# M0 register map
Registers are 32-bit, read-write, reset 0x0 unless marked. A register's access mark holds for its fields unless they carry their own. Offsets are from the block's base; lines under a group give offsets from that group; [hi:lo] are bit positions; {n}, {i} and the like mark numbered series; 'fields as' and 'values as' point back to an identical list; <NAME> marks a mode.

## Memory map
0xE000E010 STK size 0x11 — SysTick timer
0xE000E100 NVIC size 0x33D — Nested Vectored Interrupt Controller
0xE000ED00 SCB size 0x41 — System control block

## NVIC — Nested Vectored Interrupt Controller
Base 0xE000E100
0x00 ISER — Interrupt Set Enable Register
  [31:0] SETENA
0x80 ICER — Interrupt Clear Enable Register
  [31:0] CLRENA
0x100 ISPR — Interrupt Set-Pending Register
  [31:0] SETPEND
0x180 ICPR — Interrupt Clear-Pending Register
  [31:0] CLRPEND
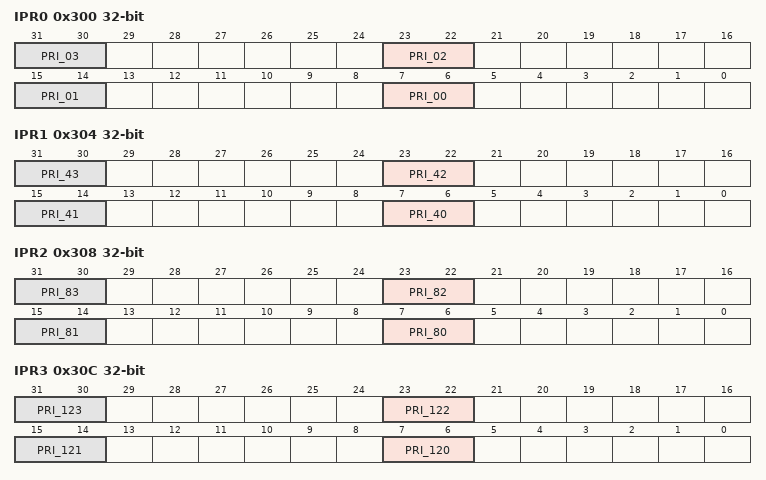
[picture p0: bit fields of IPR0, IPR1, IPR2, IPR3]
0x300 IPR0 — Interrupt Priority Register 0
  [8n+7:8n+6] PRI_{n:02} (n=0..3)
0x304 IPR1 — Interrupt Priority Register 1
  [8n-313:8n-314] PRI_{n} (n=40..43)
0x308 IPR2 — Interrupt Priority Register 2
  [8n-633:8n-634] PRI_{n} (n=80..83)
0x30C IPR3 — Interrupt Priority Register 3
  [8n-953:8n-954] PRI_{n} (n=120..123)
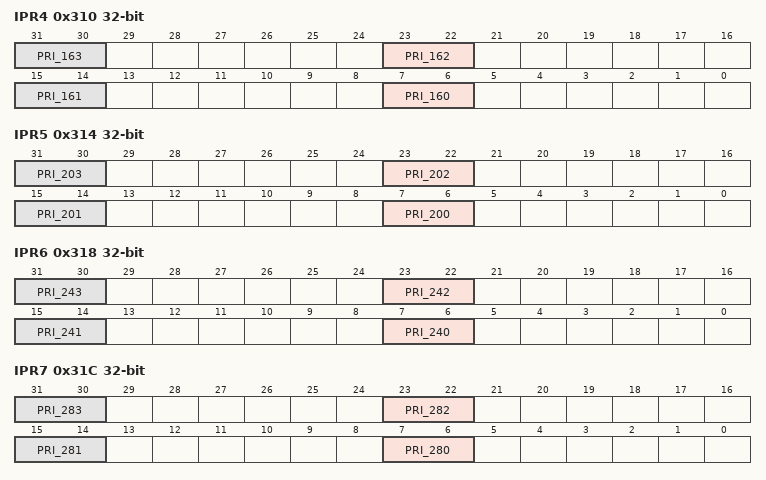
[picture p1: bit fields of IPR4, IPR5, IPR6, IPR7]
0x310 IPR4 — Interrupt Priority Register 4
  [8n-1273:8n-1274] PRI_{n} (n=160..163)
0x314 IPR5 — Interrupt Priority Register 5
  [8n-1593:8n-1594] PRI_{n} (n=200..203)
0x318 IPR6 — Interrupt Priority Register 6
  [8n-1913:8n-1914] PRI_{n} (n=240..243)
0x31C IPR7 — Interrupt Priority Register 7
  [8n-2233:8n-2234] PRI_{n} (n=280..283)

## SCB — System control block
Base 0xE000ED00
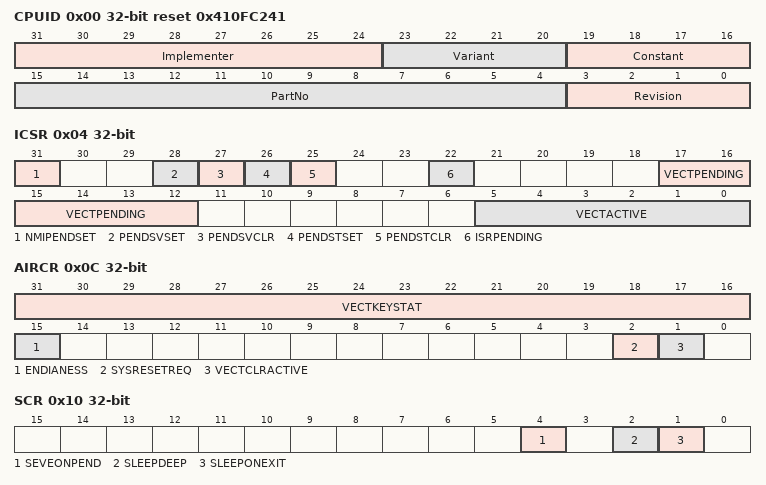
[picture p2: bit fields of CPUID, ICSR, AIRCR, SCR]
0x00 CPUID ro reset 0x410FC241 — CPUID base register
  [31:24] Implementer — Implementer code
  [23:20] Variant — Variant number
  [19:16] Constant — Reads as 0xF
  [15:4] PartNo — Part number of the processor
  [3:0] Revision — Revision number
0x04 ICSR — Interrupt control and state register
  [31] NMIPENDSET — NMI set-pending bit.
  [28] PENDSVSET — PendSV set-pending bit
  [27] PENDSVCLR — PendSV clear-pending bit
  [26] PENDSTSET — SysTick exception set-pending bit
  [25] PENDSTCLR — SysTick exception clear-pending bit
  [22] ISRPENDING — Interrupt pending flag
  [17:12] VECTPENDING — Pending vector
  [5:0] VECTACTIVE — Active vector
0x0C AIRCR — Application interrupt and reset control register
  [31:16] VECTKEYSTAT — Register key
  [15] ENDIANESS
  [2] SYSRESETREQ
  [1] VECTCLRACTIVE
0x10 SCR — System control register
  [4] SEVEONPEND — Send Event on Pending bit
  [2] SLEEPDEEP
  [1] SLEEPONEXIT
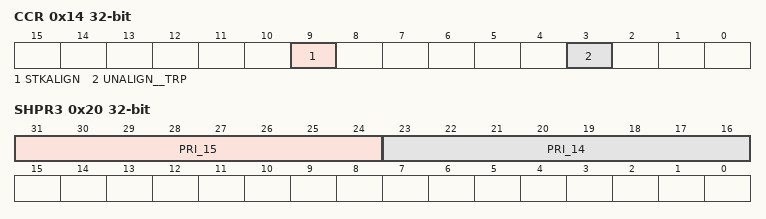
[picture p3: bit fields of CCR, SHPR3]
0x14 CCR — Configuration and control register
  [9] STKALIGN, [3] UNALIGN__TRP
0x1C SHPR2 — System handler priority registers
  [31:24] PRI_11 — Priority of system handler 11
0x20 SHPR3 — System handler priority registers
  [31:24] PRI_15 — Priority of system handler 15
  [23:16] PRI_14 — Priority of system handler 14

## STK — SysTick timer
Base 0xE000E010
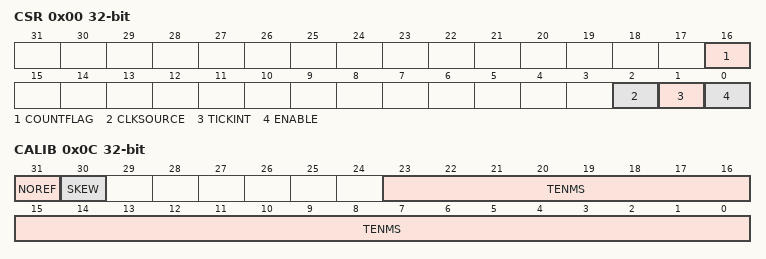
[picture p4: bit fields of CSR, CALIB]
0x00 CSR — SysTick control and status register
  [16] COUNTFLAG
  [2] CLKSOURCE — Clock source selection
  [1] TICKINT — SysTick exception request enable
  [0] ENABLE — Counter enable
0x04 RVR — SysTick reload value register
  [23:0] RELOAD — RELOAD value
0x08 CVR — SysTick current value register
  [23:0] CURRENT — Current counter value
0x0C CALIB — SysTick calibration value register
  [31] NOREF — NOREF flag. Reads as zero
  [30] SKEW — SKEW flag: Indicates whether the TENMS value is exact
  [23:0] TENMS — Calibration value
